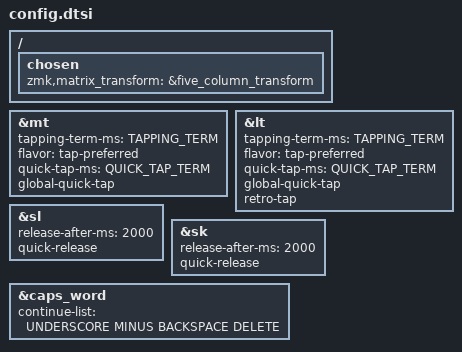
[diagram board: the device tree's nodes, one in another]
/*
*
* Copyright (c) 2022 Rafael Romão
* SPDX-License-Identifier: MIT
*
*/

/ {
  chosen {
    zmk,matrix_transform = &five_column_transform;
  };
};

#define ROMAK 0
#define NUMPAD 1
#define ACCENT 2
#define MACROS 3
#define LOWER 4
#define RAISE 5
#define NAV_F 6
#define MED 7
#define NAV 8
#define LOCK_KB 9
#define MAINT 10

#define TAPPING_TERM 175
#define QUICK_TAP_TERM 200

&mt {
    tapping-term-ms = <TAPPING_TERM>;
    flavor = "tap-preferred";
    quick-tap-ms = <QUICK_TAP_TERM>;
    global-quick-tap;
};

&lt {
    tapping-term-ms = <TAPPING_TERM>;
    flavor = "tap-preferred";
    quick-tap-ms = <QUICK_TAP_TERM>;
    global-quick-tap;
    retro-tap;
};

&sl {
    release-after-ms = <2000>;
    quick-release;
};

&sk {
    release-after-ms = <2000>;
    quick-release;
};

&caps_word {
  continue-list = <UNDERSCORE MINUS BACKSPACE DELETE>;
};
